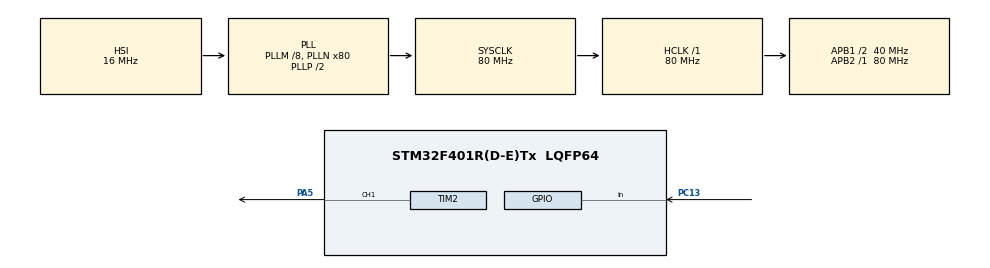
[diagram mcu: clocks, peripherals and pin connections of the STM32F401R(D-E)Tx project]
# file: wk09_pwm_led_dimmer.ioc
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Mcu.Family=STM32F4
RCC.CortexFreq_Value=80000000
RCC.APB1CLKDivider=RCC_HCLK_DIV2
RCC.SYSCLKSource=RCC_SYSCLKSOURCE_PLLCLK
ProjectManager.StackSize=0x400
TIM2.Pulse-PWM\ Generation1\ CH1=312
PA13.Signal=SYS_JTMS-SWDIO
ProjectManager.TargetToolchain=STM32CubeIDE
RCC.HCLKFreq_Value=80000000
RCC.APB2TimFreq_Value=80000000
RCC.LSE_VALUE=32768
RCC.AHBFreq_Value=80000000
PA5.Signal=S_TIM2_CH1_ETR
RCC.HSE_VALUE=25000000
board=custom
PC13-ANTI_TAMP.Signal=GPIO_Input
RCC.VCOOutputFreq_Value=160000000
RCC.APB2Freq_Value=80000000
PA14.Mode=Serial_Wire
TIM2.Channel-PWM\ Generation1\ CH1=TIM_CHANNEL_1
TIM2.Period=624
PA13.Mode=Serial_Wire
Mcu.Name=STM32F401R(D-E)Tx
RCC.48MHZClocksFreq_Value=40000000
RCC.SYSCLKFreq_VALUE=80000000
Mcu.Package=LQFP64
TIM2.Prescaler=127
SH.S_TIM2_CH1_ETR.0=TIM2_CH1,PWM Generation1 CH1
PA14.Signal=SYS_JTCK-SWCLK
ProjectManager.HeapSize=0x200
RCC.HSI_VALUE=16000000
NVIC.PriorityGroup=NVIC_PRIORITYGROUP_4
RCC.PLLM=8
RCC.PLLN=80
RCC.APB1TimFreq_Value=80000000
RCC.APB1Freq_Value=40000000

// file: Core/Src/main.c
/* USER CODE BEGIN Header */
/**
  ******************************************************************************
  * @file           : main.c
  * @brief          : Main program body
  ******************************************************************************
  * @attention
  *
  * <h2><center>&copy; Copyright (c) 2021 STMicroelectronics.
  * All rights reserved.</center></h2>
  *
  * This software component is licensed by ST under BSD 3-Clause license,
  * the "License"; You may not use this file except in compliance with the
  * License. You may obtain a copy of the License at:
  *                        opensource.org/licenses/BSD-3-Clause
  *
  ******************************************************************************
  */
/* USER CODE END Header */
#include "main.h"

TIM_HandleTypeDef htim2;

void SystemClock_Config(void);
static void MX_GPIO_Init(void);
static void MX_TIM2_Init(void);

int main(void)
{

  /* MCU Configuration--------------------------------------------------------*/

  /* Reset of all peripherals, Initializes the Flash interface and the Systick. */
  HAL_Init();

  /* Configure the system clock */
  SystemClock_Config();

  /* Initialize all configured peripherals */
  MX_GPIO_Init();
  MX_TIM2_Init();
  /* USER CODE BEGIN 2 */
  HAL_TIM_PWM_Start(&htim2, TIM_CHANNEL_1);
  /* USER CODE END 2 */

  /* Infinite loop */
  while (1)
  {

    /* USER CODE BEGIN 3 */
	TIM2->CCR1 = 312; // Duty cycle 50%

  }
  /* USER CODE END 3 */
}

void SystemClock_Config(void)
{
  RCC_OscInitTypeDef RCC_OscInitStruct = {0};
  RCC_ClkInitTypeDef RCC_ClkInitStruct = {0};

  /** Configure the main internal regulator output voltage
  */
  __HAL_RCC_PWR_CLK_ENABLE();
  __HAL_PWR_VOLTAGESCALING_CONFIG(PWR_REGULATOR_VOLTAGE_SCALE2);
  /** Initializes the RCC Oscillators according to the specified parameters
  * in the RCC_OscInitTypeDef structure.
  */
  RCC_OscInitStruct.OscillatorType = RCC_OSCILLATORTYPE_HSI;
  RCC_OscInitStruct.HSIState = RCC_HSI_ON;
  RCC_OscInitStruct.HSICalibrationValue = RCC_HSICALIBRATION_DEFAULT;
  RCC_OscInitStruct.PLL.PLLState = RCC_PLL_ON;
  RCC_OscInitStruct.PLL.PLLSource = RCC_PLLSOURCE_HSI;
  RCC_OscInitStruct.PLL.PLLM = 8;
  RCC_OscInitStruct.PLL.PLLN = 80;
  RCC_OscInitStruct.PLL.PLLP = RCC_PLLP_DIV2;
  RCC_OscInitStruct.PLL.PLLQ = 4;
  if (HAL_RCC_OscConfig(&RCC_OscInitStruct) != HAL_OK)
  {
    Error_Handler();
  }
  /** Initializes the CPU, AHB and APB buses clocks
  */
  RCC_ClkInitStruct.ClockType = RCC_CLOCKTYPE_HCLK|RCC_CLOCKTYPE_SYSCLK
                              |RCC_CLOCKTYPE_PCLK1|RCC_CLOCKTYPE_PCLK2;
  RCC_ClkInitStruct.SYSCLKSource = RCC_SYSCLKSOURCE_PLLCLK;
  RCC_ClkInitStruct.AHBCLKDivider = RCC_SYSCLK_DIV1;
  RCC_ClkInitStruct.APB1CLKDivider = RCC_HCLK_DIV2;
  RCC_ClkInitStruct.APB2CLKDivider = RCC_HCLK_DIV1;

  if (HAL_RCC_ClockConfig(&RCC_ClkInitStruct, FLASH_LATENCY_2) != HAL_OK)
  {
    Error_Handler();
  }
}

static void MX_TIM2_Init(void)
{

  TIM_MasterConfigTypeDef sMasterConfig = {0};
  TIM_OC_InitTypeDef sConfigOC = {0};

  htim2.Instance = TIM2;
  htim2.Init.Prescaler = 127;
  htim2.Init.CounterMode = TIM_COUNTERMODE_UP;
  htim2.Init.Period = 624;
  htim2.Init.ClockDivision = TIM_CLOCKDIVISION_DIV1;
  htim2.Init.AutoReloadPreload = TIM_AUTORELOAD_PRELOAD_DISABLE;
  if (HAL_TIM_PWM_Init(&htim2) != HAL_OK)
  {
    Error_Handler();
  }
  sMasterConfig.MasterOutputTrigger = TIM_TRGO_RESET;
  sMasterConfig.MasterSlaveMode = TIM_MASTERSLAVEMODE_DISABLE;
  if (HAL_TIMEx_MasterConfigSynchronization(&htim2, &sMasterConfig) != HAL_OK)
  {
    Error_Handler();
  }
  sConfigOC.OCMode = TIM_OCMODE_PWM1;
  sConfigOC.Pulse = 312;
  sConfigOC.OCPolarity = TIM_OCPOLARITY_HIGH;
  sConfigOC.OCFastMode = TIM_OCFAST_DISABLE;
  if (HAL_TIM_PWM_ConfigChannel(&htim2, &sConfigOC, TIM_CHANNEL_1) != HAL_OK)
  {
    Error_Handler();
  }
  HAL_TIM_MspPostInit(&htim2);

}

static void MX_GPIO_Init(void)
{
  GPIO_InitTypeDef GPIO_InitStruct = {0};

  /* GPIO Ports Clock Enable */
  __HAL_RCC_GPIOC_CLK_ENABLE();
  __HAL_RCC_GPIOA_CLK_ENABLE();

  /*Configure GPIO pin : PC13 */
  GPIO_InitStruct.Pin = GPIO_PIN_13;
  GPIO_InitStruct.Mode = GPIO_MODE_INPUT;
  GPIO_InitStruct.Pull = GPIO_NOPULL;
  HAL_GPIO_Init(GPIOC, &GPIO_InitStruct);

}

void Error_Handler(void)
{
  __disable_irq();
  while (1)
  {
  }
}

/************************ (C) COPYRIGHT STMicroelectronics *****END OF FILE****/
